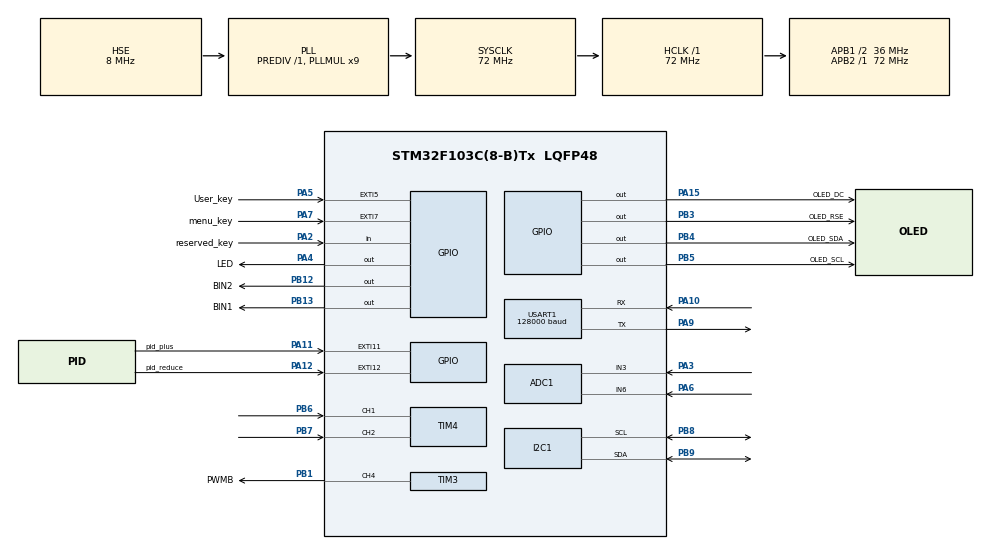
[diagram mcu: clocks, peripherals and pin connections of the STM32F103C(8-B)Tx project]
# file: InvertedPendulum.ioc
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ADC1.Channel-2\#ChannelRegularConversion=ADC_CHANNEL_3
ADC1.ContinuousConvMode=DISABLE
ADC1.EnableRegularConversion=ENABLE
ADC1.NbrOfConversion=1
ADC1.NbrOfConversionFlag=1
ADC1.Rank-2\#ChannelRegularConversion=1
ADC1.SamplingTime-2\#ChannelRegularConversion=ADC_SAMPLETIME_1CYCLE_5
ADC1.master=1
I2C1.I2C_Mode=I2C_Fast
Mcu.Family=STM32F1
Mcu.Name=STM32F103C(8-B)Tx
Mcu.Package=LQFP48
NVIC.EXTI15_10_IRQn=true\:2\:2\:true\:false\:true\:true\:true
NVIC.EXTI9_5_IRQn=true\:2\:2\:true\:false\:true\:true\:true
NVIC.PriorityGroup=NVIC_PRIORITYGROUP_2
NVIC.TIM1_UP_IRQn=true\:1\:3\:true\:false\:true\:true\:true
PA10.Mode=Asynchronous
PA10.Signal=USART1_RX
PA11.GPIO_Label=pid_plus
PA11.GPIO_ModeDefaultEXTI=GPIO_MODE_IT_FALLING
PA11.GPIO_PuPd=GPIO_PULLUP
PA11.Signal=GPXTI11
PA12.GPIO_Label=pid_reduce
PA12.GPIO_ModeDefaultEXTI=GPIO_MODE_IT_FALLING
PA12.GPIO_PuPd=GPIO_PULLUP
PA12.Signal=GPXTI12
PA13.Mode=Serial_Wire
PA13.Signal=SYS_JTMS-SWDIO
PA14.Mode=Serial_Wire
PA14.Signal=SYS_JTCK-SWCLK
PA15.GPIO_Label=OLED_DC
PA15.GPIO_Speed=GPIO_SPEED_FREQ_HIGH
PA15.Signal=GPIO_Output
PA2.GPIO_Label=reserved_key
PA2.GPIO_Mode=GPIO_MODE_INPUT
PA2.GPIO_PuPd=GPIO_PULLUP
PA2.Signal=GPIO_Input
PA3.Signal=ADCx_IN3
PA4.GPIO_Label=LED
PA4.GPIO_ModeDefaultOutputPP=GPIO_MODE_OUTPUT_PP
PA4.GPIO_PuPd=GPIO_PULLUP
PA4.GPIO_Speed=GPIO_SPEED_FREQ_HIGH
PA4.PinState=GPIO_PIN_SET
PA4.Signal=GPIO_Output
PA5.GPIO_Label=User_key
PA5.GPIO_ModeDefaultEXTI=GPIO_MODE_IT_FALLING
PA5.GPIO_PuPd=GPIO_PULLUP
PA5.Signal=GPXTI5
PA6.Signal=ADCx_IN6
PA7.GPIO_Label=menu_key
PA7.GPIO_ModeDefaultEXTI=GPIO_MODE_IT_FALLING
PA7.GPIO_PuPd=GPIO_PULLUP
PA7.Signal=GPXTI7
PA9.Mode=Asynchronous
PA9.Signal=USART1_TX
PB1.GPIO_Label=PWMB
PB1.GPIO_Speed=GPIO_SPEED_FREQ_HIGH
PB1.Signal=S_TIM3_CH4
PB12.GPIO_Label=BIN2
PB12.GPIO_Speed=GPIO_SPEED_FREQ_HIGH
PB12.Signal=GPIO_Output
PB13.GPIO_Label=BIN1
PB13.GPIO_Speed=GPIO_SPEED_FREQ_HIGH
PB13.Signal=GPIO_Output
PB3.GPIO_Label=OLED_RSE
PB3.GPIO_Speed=GPIO_SPEED_FREQ_HIGH
PB3.Signal=GPIO_Output
PB4.GPIO_Label=OLED_SDA
PB4.GPIO_Speed=GPIO_SPEED_FREQ_HIGH
PB4.Signal=GPIO_Output
PB5.GPIO_Label=OLED_SCL
PB5.Signal=GPIO_Output
PB6.Signal=S_TIM4_CH1
PB7.Signal=S_TIM4_CH2
PB8.Mode=I2C
PB8.Signal=I2C1_SCL
PB9.Mode=I2C
PB9.Signal=I2C1_SDA
PD0-OSC_IN.Mode=HSE-External-Oscillator
PD0-OSC_IN.Signal=RCC_OSC_IN
PD1-OSC_OUT.Mode=HSE-External-Oscillator
PD1-OSC_OUT.Signal=RCC_OSC_OUT
ProjectManager.HeapSize=0x200
ProjectManager.StackSize=0x400
ProjectManager.TargetToolchain=STM32CubeIDE
RCC.ADCPresc=RCC_ADCPCLK2_DIV6
RCC.AHBFreq_Value=72000000
RCC.APB1CLKDivider=RCC_HCLK_DIV2
RCC.APB1Freq_Value=36000000
RCC.APB1TimFreq_Value=72000000
RCC.APB2Freq_Value=72000000
RCC.APB2TimFreq_Value=72000000
RCC.HCLKFreq_Value=72000000
RCC.PLLMUL=RCC_PLL_MUL9
RCC.PLLSourceVirtual=RCC_PLLSOURCE_HSE
RCC.SYSCLKFreq_VALUE=72000000
RCC.SYSCLKSource=RCC_SYSCLKSOURCE_PLLCLK
RCC.TimSys_Div=SYSTICK_CLKSOURCE_HCLK_DIV8
RCC.USBFreq_Value=72000000
SH.ADCx_IN3.0=ADC1_IN3,IN3
SH.ADCx_IN6.0=ADC1_IN6,IN6
SH.S_TIM3_CH4.0=TIM3_CH4,PWM Generation4 CH4
SH.S_TIM4_CH1.0=TIM4_CH1,Encoder_Interface
SH.S_TIM4_CH2.0=TIM4_CH2,Encoder_Interface
TIM1.Period=49
TIM1.Prescaler=7199
TIM3.Channel-PWM\ Generation4\ CH4=TIM_CHANNEL_4
TIM3.Period=7199
TIM4.EncoderMode=TIM_ENCODERMODE_TI12
TIM4.IC1Filter=10
TIM4.IC2Filter=10
USART1.BaudRate=128000
USART1.VirtualMode=VM_ASYNC
VP_TIM1_VS_ClockSourceINT.Mode=Internal
VP_TIM3_VS_ClockSourceINT.Mode=Internal
board=custom

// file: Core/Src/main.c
/* USER CODE BEGIN Header */
/**
  ******************************************************************************
  * @file           : main.c
  * @brief          : Main program body
  ******************************************************************************
  * @attention
  *
  * Copyright (c) 2022 STMicroelectronics.
  * All rights reserved.
  *
  * This software is licensed under terms that can be found in the LICENSE file
  * in the root directory of this software component.
  * If no LICENSE file comes with this software, it is provided AS-IS.
  *
  ******************************************************************************
  */
/* USER CODE END Header */
#include "main.h"
#include "adc.h"
#include "i2c.h"
#include "tim.h"
#include "usart.h"
#include "gpio.h"
#include "oled.h"

void SystemClock_Config(void);

int main(void)
{

  /* MCU Configuration--------------------------------------------------------*/

  /* Reset of all peripherals, Initializes the Flash interface and the Systick. */
  HAL_Init();

  /* Configure the system clock */
  SystemClock_Config();

  /* Initialize all configured peripherals */
  MX_GPIO_Init();
  MX_TIM3_Init();
  MX_TIM4_Init();
  MX_USART1_UART_Init();
  MX_ADC1_Init();
  MX_TIM1_Init();
  MX_I2C1_Init();
  /* USER CODE BEGIN 2 */
  OLED_Init();
  /* USER CODE END 2 */

  /* Infinite loop */
  while (1)
  {

    /* USER CODE BEGIN 3 */
	  OLED_Clear();
	  oled_show();
  }
  /* USER CODE END 3 */
}

void SystemClock_Config(void)
{
  RCC_OscInitTypeDef RCC_OscInitStruct = {0};
  RCC_ClkInitTypeDef RCC_ClkInitStruct = {0};
  RCC_PeriphCLKInitTypeDef PeriphClkInit = {0};

  /** Initializes the RCC Oscillators according to the specified parameters
  * in the RCC_OscInitTypeDef structure.
  */
  RCC_OscInitStruct.OscillatorType = RCC_OSCILLATORTYPE_HSE;
  RCC_OscInitStruct.HSEState = RCC_HSE_ON;
  RCC_OscInitStruct.HSEPredivValue = RCC_HSE_PREDIV_DIV1;
  RCC_OscInitStruct.HSIState = RCC_HSI_ON;
  RCC_OscInitStruct.PLL.PLLState = RCC_PLL_ON;
  RCC_OscInitStruct.PLL.PLLSource = RCC_PLLSOURCE_HSE;
  RCC_OscInitStruct.PLL.PLLMUL = RCC_PLL_MUL9;
  if (HAL_RCC_OscConfig(&RCC_OscInitStruct) != HAL_OK)
  {
    Error_Handler();
  }
  /** Initializes the CPU, AHB and APB buses clocks
  */
  RCC_ClkInitStruct.ClockType = RCC_CLOCKTYPE_HCLK|RCC_CLOCKTYPE_SYSCLK
                              |RCC_CLOCKTYPE_PCLK1|RCC_CLOCKTYPE_PCLK2;
  RCC_ClkInitStruct.SYSCLKSource = RCC_SYSCLKSOURCE_PLLCLK;
  RCC_ClkInitStruct.AHBCLKDivider = RCC_SYSCLK_DIV1;
  RCC_ClkInitStruct.APB1CLKDivider = RCC_HCLK_DIV2;
  RCC_ClkInitStruct.APB2CLKDivider = RCC_HCLK_DIV1;

  if (HAL_RCC_ClockConfig(&RCC_ClkInitStruct, FLASH_LATENCY_2) != HAL_OK)
  {
    Error_Handler();
  }
  PeriphClkInit.PeriphClockSelection = RCC_PERIPHCLK_ADC;
  PeriphClkInit.AdcClockSelection = RCC_ADCPCLK2_DIV6;
  if (HAL_RCCEx_PeriphCLKConfig(&PeriphClkInit) != HAL_OK)
  {
    Error_Handler();
  }
}

void Error_Handler(void)
{
  __disable_irq();
  while (1)
  {
  }
}
